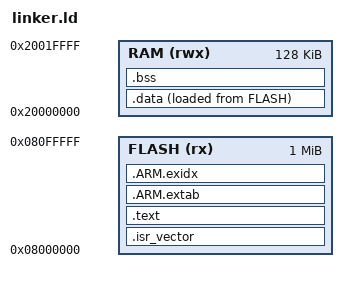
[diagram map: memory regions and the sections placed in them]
ENTRY(Reset_Handler)
MEMORY
{
  FLASH (rx)  : ORIGIN = 0x08000000, LENGTH = 1M
  RAM   (rwx) : ORIGIN = 0x20000000, LENGTH = 128K
}
_estack = ORIGIN(RAM) + LENGTH(RAM);
SECTIONS
{
  .isr_vector : { KEEP(*(.isr_vector)) } > FLASH
  .text : { *(.text*) *(.rodata*) . = ALIGN(4); } > FLASH
  .ARM.extab : { *(.ARM.extab* .gnu.linkonce.armextab.*) } > FLASH
  .ARM.exidx : { *(.ARM.exidx* .gnu.linkonce.armexidx.*) } > FLASH
  _sidata = LOADADDR(.data);
  .data : { _sdata = .; *(.data*) . = ALIGN(4); _edata = .; } > RAM AT > FLASH
  .bss : { _sbss = .; *(.bss*) *(COMMON) . = ALIGN(4); _ebss = .; } > RAM
  PROVIDE(end = .);
  PROVIDE(_end = .);
}
